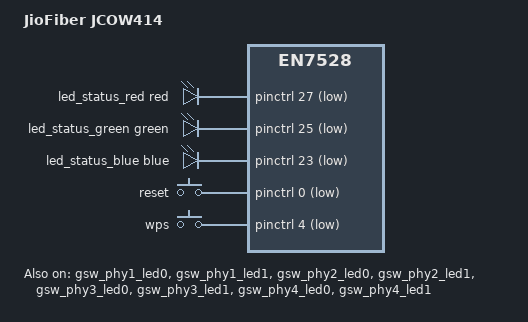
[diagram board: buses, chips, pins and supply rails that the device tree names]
// SPDX-License-Identifier: (GPL-2.0-only OR BSD-2-Clause)
/dts-v1/;

#include "en7528_jiofiber.dtsi"

/ {
	model = "JioFiber JCOW414";
	compatible = "jiofiber,jcow414", "econet,en7528";

	aliases {
		led-boot = &led_status_red;
		led-failsafe = &led_status_red;
		led-running = &led_status_green;
		led-upgrade = &led_status_blue;
	};

	leds {
		compatible = "gpio-leds";

		led_status_red: status-red {
			color = <LED_COLOR_ID_RED>;
			function = LED_FUNCTION_STATUS;
			gpios = <&pinctrl 27 GPIO_ACTIVE_LOW>;
		};

		led_status_green: status-green {
			color = <LED_COLOR_ID_GREEN>;
			function = LED_FUNCTION_STATUS;
			gpios = <&pinctrl 25 GPIO_ACTIVE_LOW>;
		};

		led_status_blue: status-blue {
			color = <LED_COLOR_ID_BLUE>;
			function = LED_FUNCTION_STATUS;
			gpios = <&pinctrl 23 GPIO_ACTIVE_LOW>;
		};
	};

	keys {
		compatible = "gpio-keys";

		key-reset {
			label = "reset";
			gpios = <&pinctrl 0 GPIO_ACTIVE_LOW>;
			linux,code = <KEY_RESTART>;
		};

		key-wps {
			label = "wps";
			gpios = <&pinctrl 4 GPIO_ACTIVE_LOW>;
			linux,code = <KEY_WPS_BUTTON>;
		};
	};
};

&gsw_phy1_led0 {
	color = <LED_COLOR_ID_GREEN>;
	function = LED_FUNCTION_LAN;
	function-enumerator = <1>;
	active-low;
	status = "okay";
};

&gsw_phy1_led1 {
	color = <LED_COLOR_ID_AMBER>;
	function = LED_FUNCTION_LAN;
	function-enumerator = <1>;
	active-low;
	status = "okay";
};

&gsw_phy2_led0 {
	color = <LED_COLOR_ID_GREEN>;
	function = LED_FUNCTION_LAN;
	function-enumerator = <2>;
	active-low;
	status = "okay";
};

&gsw_phy2_led1 {
	color = <LED_COLOR_ID_AMBER>;
	function = LED_FUNCTION_LAN;
	function-enumerator = <2>;
	active-low;
	status = "okay";
};

&gsw_phy3_led0 {
	color = <LED_COLOR_ID_GREEN>;
	function = LED_FUNCTION_LAN;
	function-enumerator = <3>;
	active-low;
	status = "okay";
};

&gsw_phy3_led1 {
	color = <LED_COLOR_ID_AMBER>;
	function = LED_FUNCTION_LAN;
	function-enumerator = <3>;
	active-low;
	status = "okay";
};

&gsw_phy4_led0 {
	color = <LED_COLOR_ID_GREEN>;
	function = LED_FUNCTION_LAN;
	function-enumerator = <4>;
	active-low;
	status = "okay";
};

&gsw_phy4_led1 {
	color = <LED_COLOR_ID_AMBER>;
	function = LED_FUNCTION_LAN;
	function-enumerator = <4>;
	active-low;
	status = "okay";
};
